# STM32WBA54 register map
File version: 1.0
CPU: CM33 r0p1, little endian, MPU, FPU, 4 interrupt priority bits
Registers are 32-bit, read-write, reset 0x0 unless marked. A register's access mark holds for its fields unless they carry their own. Offsets are from the block's base; [hi:lo] are bit positions.

## RCC (part 2 of 2) — Reset and clock control
Base 0x46020C00
Same registers: SEC_RCC 0x56020C00
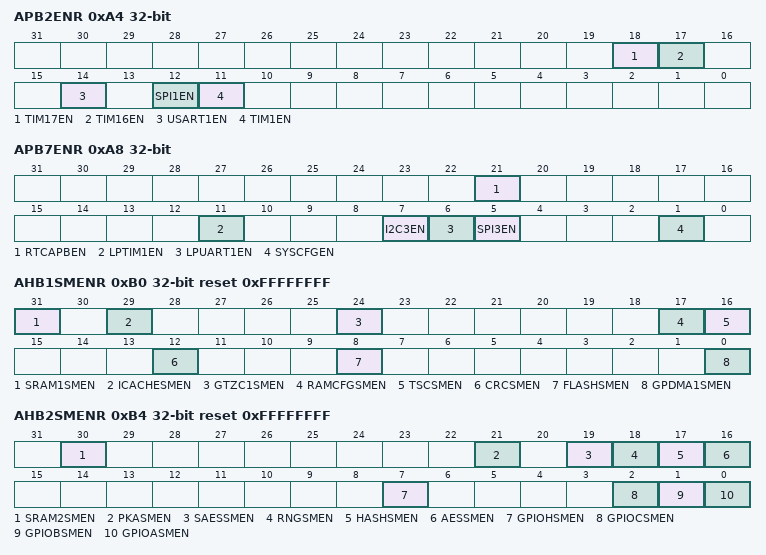
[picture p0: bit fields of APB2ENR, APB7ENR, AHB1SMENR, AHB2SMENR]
0xA4 APB2ENR — RCC APB2 peripheral clock enable register
  [18] TIM17EN — TIM17 bus and kernel clocks enable Set and cleared by software. Access can be secured by GTZC_TZSC TIM17SEC. When secure, a non-secure read/write access is RAZ/WI. It does not generate an illegal access interrupt. This bit can be protected against unprivileged access when secure with RCC SPRIV or when non-secure with RCC NSPRIV.
  [17] TIM16EN — TIM16 bus and kernel clocks enable Set and cleared by software. Access can be secured by GTZC_TZSC TIM16SEC. When secure, a non-secure read/write access is RAZ/WI. It does not generate an illegal access interrupt. This bit can be protected against unprivileged access when secure with RCC SPRIV or when non-secure with RCC NSPRIV.
  [14] USART1EN — USART1bus and kernel clocks enable Set and cleared by software. Access can be secured by GTZC_TZSC USART1SEC. When secure, a non-secure read/write access is RAZ/WI. It does not generate an illegal access interrupt. This bit can be protected against unprivileged access when secure with RCC SPRIV or when non-secure with RCC NSPRIV.
  [12] SPI1EN — SPI1 bus and kernel clocks enable Set and cleared by software. Access can be secured by GTZC_TZSC SPI1SEC. When secure, a non-secure read/write access is RAZ/WI. It does not generate an illegal access interrupt. This bit can be protected against unprivileged access when secure with RCC SPRIV or when non-secure with RCC NSPRIV.
  [11] TIM1EN — TIM1 bus and kernel clocks enable Set and cleared by software. Access can be secured by GTZC_TZSC TIM1SEC. When secure, a non-secure read/write access is RAZ/WI. It does not generate an illegal access interrupt. This bit can be protected against unprivileged access when secure with RCC SPRIV or when non-secure with RCC NSPRIV.
0xA8 APB7ENR — RCC APB7 peripheral clock enable register
  [21] RTCAPBEN — RTC and TAMP bus clock enable Set and cleared by software. Can only be accessed secure when one or more features in the RTC or TAMP is/are secure. When secure, a non-secure read/write access is RAZ/WI. It does not generate an illegal access interrupt. This bit can be protected against unprivileged access when secure with RCC SPRIV or when non-secure with RCC NSPRIV.
  [11] LPTIM1EN — LPTIM1 bus and kernel clocks enable Set and cleared by software. Access can be secured by GTZC_TZSC LPTIM1SEC. When secure, a non-secure read/write access is RAZ/WI. It does not generate an illegal access interrupt. This bit can be protected against unprivileged access when secure with RCC SPRIV or when non-secure with RCC NSPRIV.
  [7] I2C3EN — I2C3 bus and kernel clocks enable Set and cleared by software. Access can be secured by GTZC_TZSC I2C3SEC. When secure, a non-secure read/write access is RAZ/WI. It does not generate an illegal access interrupt. This bit can be protected against unprivileged access when secure with RCC SPRIV or when non-secure with RCC NSPRIV.
  [6] LPUART1EN — LPUART1 bus and kernel clocks enable Set and cleared by software. Access can be secured by GTZC_TZSC LPUART1SEC. When secure, a non-secure read/write access is RAZ/WI. It does not generate an illegal access interrupt. This bit can be protected against unprivileged access when secure with RCC SPRIV or when non-secure with RCC NSPRIV.
  [5] SPI3EN — SPI3 bus and kernel clocks enable Set and cleared by software. Access can be secured by GTZC_TZSC SPI3SEC. When secure, a non-secure read/write access is RAZ/WI. It does not generate an illegal access interrupt. This bit can be protected against unprivileged access when secure with RCC SPRIV or when non-secure with RCC NSPRIV.
  [1] SYSCFGEN — SYSCFG bus clock enable Set and cleared by software. Access can be secured by SYSCFG SYSCFGSEC. When secure, a non-secure read/write access is RAZ/WI. It does not generate an illegal access interrupt. This bit can be protected against unprivileged access when secure with RCC SPRIV or when non-secure with RCC NSPRIV.
0xB0 AHB1SMENR reset 0xFFFFFFFF — RCC AHB1 peripheral clocks enable in Sleep and Stop modes register
  [31] SRAM1SMEN — SRAM1 bus clock enable during Sleep and Stop modes Set and cleared by software. Access can be secured by GTZC_MPCBB1 SECx, INVSECSTATE. When secure, a non-secure read/write access is RAZ/WI. It does not generate an illegal access interrupt. This bit can be protected against unprivileged access when secure with RCC SPRIV or when non-secure with RCC NSPRIV.
  [29] ICACHESMEN — ICACHE bus clock enable during Sleep and Stop modes Set and cleared by software. Access can be secured by GTZC_TZSC ICACHE_REGSEC. When secure, a non-secure read/write access is RAZ/WI. It does not generate an illegal access interrupt. This bit can be protected against unprivileged access when secure with RCC SPRIV or when non-secure with RCC NSPRIV..
  [24] GTZC1SMEN — GTZC1 bus clock enable during Sleep and Stop modes Set and cleared by software. Can only be accessed secure when one device is secure (TZEN = 1). When secure, a non-secure read/write access is RAZ/WI. It does not generate an illegal access interrupt. This bit can be protected against unprivileged access when secure with RCC SPRIV or when non-secure with RCC NSPRIV.
  [17] RAMCFGSMEN — RAMCFG bus clock enable during Sleep and Stop modes Set and cleared by software. Access can be secured by GTZC_TZSC RAMCFGSEC. When secure, a non-secure read/write access is RAZ/WI. It does not generate an illegal access interrupt. This bit can be protected against unprivileged access when secure with RCC SPRIV or when non-secure with RCC NSPRIV.
  [16] TSCSMEN — TSC bus clock enable during Sleep and Stop modes Set and cleared by software. Access can be secured by GTZC_TZSC TSCSEC. When secure, a non-secure read/write access is RAZ/WI. It does not generate an illegal access interrupt. This bit can be protected against unprivileged access when secure with RCC SPRIV or when non-secure with RCC NSPRIV..
  [12] CRCSMEN — CRC bus clock enable during Sleep and Stop modes Set and cleared by software. Access can be secured by GTZC_TZSC CRCSEC. When secure, a non-secure read/write access is RAZ/WI. It does not generate an illegal access interrupt. This bit can be protected against unprivileged access when secure with RCC SPRIV or when non-secure with RCC NSPRIV.
  [8] FLASHSMEN — FLASH bus clock enable during Sleep and Stop modes Set and cleared by software. Can only be accessed secured when the Flash security state is secure. When secure, a non-secure read/write access is RAZ/WI. It does not generate an illegal access interrupt. This bit can be protected against unprivileged access when secure with RCC SPRIV or when non-secure with RCC NSPRIV.
  [0] GPDMA1SMEN — GPDMA1 bus clock enable during Sleep and Stop modes Set and cleared by software. Access can be secured by GPDMA1 SECx. When secure, a non-secure read/write access is RAZ/WI. It does not generate an illegal access interrupt. This bit can be protected against unprivileged access when secure with RCC SPRIV or when non-secure with RCC NSPRIV. Note: This bit must be set to allow the peripheral to wake up from Stop modes.
0xB4 AHB2SMENR reset 0xFFFFFFFF — RCC AHB2 peripheral clocks enable in Sleep and Stop modes register
  [30] SRAM2SMEN — SRAM2 bus clock enable during Sleep and Stop modes Set and cleared by software. Access can be secured by GTZC_MPCBB2 SECx, INVSECSTATE. When secure, a non-secure read/write access is RAZ/WI. It does not generate an illegal access interrupt. This bit can be protected against unprivileged access when secure with RCC SPRIV or when non-secure with RCC NSPRIV.
  [21] PKASMEN — PKA bus clock enable during Sleep and Stop modes Set and cleared by software. Access can be secured by GTZC_TZSC PKASEC. When secure, a non-secure read/write access is RAZ/WI. It does not generate an illegal access interrupt. This bit can be protected against unprivileged access when secure with RCC SPRIV or when non-secure with RCC NSPRIV.
  [19] SAESSMEN — SAES accelerator bus clock enable during Sleep and Stop modes Set and cleared by software. Access can be secured by GTZC_TZSC SAESSEC. When secure, a non-secure read/write access is RAZ/WI. It does not generate an illegal access interrupt. This bit can be protected against unprivileged access when secure with RCC SPRIV or when non-secure with RCC NSPRIV.
  [18] RNGSMEN — Random number generator (RNG) bus and kernel clocks enable during Sleep and Stop modes Set and cleared by software. Access can be secured by GTZC_TZSC RNGSEC. When secure, a non-secure read/write access is RAZ/WI. It does not generate an illegal access interrupt. This bit can be protected against unprivileged access when secure with RCC SPRIV or when non-secure with RCC NSPRIV.
  [17] HASHSMEN — HASH bus clock enable during Sleep and Stop modes Set and cleared by software. Access can be secured by GTZC_TZSC HASHSEC. When secure, a non-secure read/write access is RAZ/WI. It does not generate an illegal access interrupt. This bit can be protected against unprivileged access when secure with RCC SPRIV or when non-secure with RCC NSPRIV.
  [16] AESSMEN — AES bus clock enable during Sleep and Stop modes Set and cleared by software. Access can be secured by GTZC_TZSC AESSEC. When secure, a non-secure read/write access is RAZ/WI. It does not generate an illegal access interrupt. This bit can be protected against unprivileged access when secure with RCC SPRIV or when non-secure with RCC NSPRIV.
  [7] GPIOHSMEN — IO port H bus clock enable during Sleep and Stop modes Set and cleared by software. Access can be secured by GPIOH SECx. When secure, a non-secure read/write access is RAZ/WI. It does not generate an illegal access interrupt. This bit can be protected against unprivileged access when secure with RCC SPRIV or when non-secure with RCC NSPRIV.
  [2] GPIOCSMEN — IO port C bus clock enable during Sleep and Stop modes Set and cleared by software. Access can be secured by GPIOC SECx. When secure, a non-secure read/write access is RAZ/WI. It does not generate an illegal access interrupt. This bit can be protected against unprivileged access when secure with RCC SPRIV or when non-secure with RCC NSPRIV.
  [1] GPIOBSMEN — IO port B bus clock enable during Sleep and Stop modes Set and cleared by software. Access can be secured by GPIOB SECx. When secure, a non-secure read/write access is RAZ/WI. It does not generate an illegal access interrupt. This bit can be protected against unprivileged access when secure with RCC SPRIV or when non-secure with RCC NSPRIV.
  [0] GPIOASMEN — IO port A bus clock enable during Sleep and Stop modes Set and cleared by software. Access can be secured by GPIOA SECx. When secure, a non-secure read/write access is RAZ/WI. It does not generate an illegal access interrupt. This bit can be protected against unprivileged access when secure with RCC SPRIV or when non-secure with RCC NSPRIV.
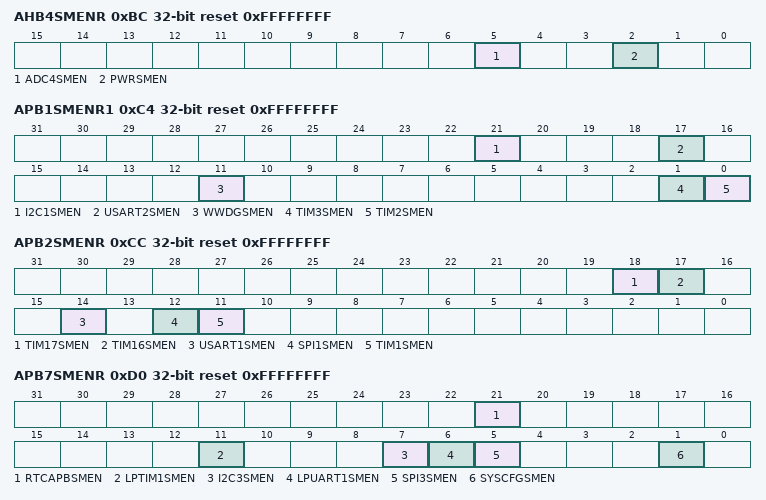
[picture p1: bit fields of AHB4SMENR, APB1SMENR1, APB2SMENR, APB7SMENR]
0xBC AHB4SMENR reset 0xFFFFFFFF — RCC AHB4 peripheral clocks enable in Sleep and Stop modes register
  [5] ADC4SMEN — ADC4 bus and kernel clocks enable during Sleep and Stop modes Set and cleared by software. Access can be secured by GTZC_TZSC ADC4SEC. When secure, a non-secure read/write access is RAZ/WI. It does not generate an illegal access interrupt. This bit can be protected against unprivileged access when secure with RCC SPRIV or when non-secure with RCC NSPRIV. Note: This bit must be set to allow the peripheral to wake up from Stop modes.
  [2] PWRSMEN — PWR bus clock enable during Sleep and Stop modes Set and cleared by software. Can only be accessed secure when one or more features in the PWR is/are secure. When secure, a non-secure read/write access is RAZ/WI. It does not generate an illegal access interrupt. This bit can be protected against unprivileged access when secure with RCC SPRIV or when non-secure with RCC NSPRIV.
0xC0 AHB5SMENR reset 0xFFFFFFFF — RCC AHB5 peripheral clocks enable in Sleep and Stop modes register
  [0] RADIOSMEN — 2.4 GHz RADIO bus clock enable during Sleep and Stop modes when the 2.4 GHz RADIO is active. Set and cleared by software. Access can be secured by GTZC_TZSC RADIOSEC. When secure, a non-secure read/write access is RAZ/WI. It does not generate an illegal access interrupt. This bit can be protected against unprivileged access when secure with RCC SPRIV or when non-secure with RCC NSPRIV.
0xC4 APB1SMENR1 reset 0xFFFFFFFF — RCC APB1 peripheral clocks enable in Sleep and Stop modes register 1
  [21] I2C1SMEN — I2C1 bus and kernel clocks enable during Sleep and Stop modes Set and cleared by software. Access can be secured by GTZC_TZSC I2C1SEC. When secure, a non-secure read/write access is RAZ/WI. It does not generate an illegal access interrupt. This bit can be protected against unprivileged access when secure with RCC SPRIV or when non-secure with RCC NSPRIV. Note: This bit must be set to allow the peripheral to wake up from Stop modes.
  [17] USART2SMEN — USART2 bus and kernel clocks enable during Sleep and Stop modes Set and cleared by software. Access can be secured by GTZC_TZSC USART2SEC. When secure, a non-secure read/write access is RAZ/WI. It does not generate an illegal access interrupt. This bit can be protected against unprivileged access when secure with RCC SPRIV or when non-secure with RCC NSPRIV. Note: This bit must be set to allow the peripheral to wake up from Stop modes.
  [11] WWDGSMEN — Window watchdog bus clock enable during Sleep and Stop modes Set and cleared by software. This bit is forced to 1 by hardware when the hardware WWDG option is activated. Access can be secured by GTZC_TZSC WWDGSEC. When secure, a non-secure read/write access is RAZ/WI. It does not generate an illegal access interrupt. This bit can be protected against unprivileged access when secure with RCC SPRIV or when non-secure with RCC NSPRIV.
  [1] TIM3SMEN — TIM3 bus and kernel clocks enable during Sleep and Stop modes Set and cleared by software. Access can be secured by GTZC_TZSC TIM3SEC. When secure, a non-secure read/write access is RAZ/WI. It does not generate an illegal access interrupt. This bit can be protected against unprivileged access when secure with RCC SPRIV or when non-secure with RCC NSPRIV.
  [0] TIM2SMEN — TIM2 bus and kernel clocks enable during Sleep and Stop modes Set and cleared by software. Access can be secured by GTZC_TZSC TIM2SEC. When secure, a non-secure read/write access is RAZ/WI. It does not generate an illegal access interrupt. This bit can be protected against unprivileged access when secure with RCC SPRIV or when non-secure with RCC NSPRIV.
0xC8 APB1SMENR2 reset 0xFFFFFFFF — RCC APB1 peripheral clocks enable in Sleep and Stop modes register 2
  [5] LPTIM2SMEN — LPTIM2 bus and kernel clocks enable during Sleep and Stop modes Set and cleared by software. Access can be secured by GTZC_TZSC LPTIM2SEC. When secure, a non-secure read/write access is RAZ/WI. It does not generate an illegal access interrupt. This bit can be protected against unprivileged access when secure with RCC SPRIV or when non-secure with RCC NSPRIV. Note: This bit must be set to allow the peripheral to wake up from Stop modes.
0xCC APB2SMENR reset 0xFFFFFFFF — RCC APB2 peripheral clocks enable in Sleep and Stop modes register
  [18] TIM17SMEN — TIM17 bus and kernel clocks enable during Sleep and Stop modes Set and cleared by software. Access can be secured by GTZC_TZSC TIM17SEC. When secure, a non-secure read/write access is RAZ/WI. It does not generate an illegal access interrupt. This bit can be protected against unprivileged access when secure with RCC SPRIV or when non-secure with RCC NSPRIV.
  [17] TIM16SMEN — TIM16 bus and kernel clocks enable during Sleep and Stop modes Set and cleared by software. Access can be secured by GTZC_TZSC TIM16SEC. When secure, a non-secure read/write access is RAZ/WI. It does not generate an illegal access interrupt. This bit can be protected against unprivileged access when secure with RCC SPRIV or when non-secure with RCC NSPRIV.
  [14] USART1SMEN — USART1 bus and kernel clocks enable during Sleep and Stop modes Set and cleared by software. Access can be secured by GTZC_TZSC USART1SEC. When secure, a non-secure read/write access is RAZ/WI. It does not generate an illegal access interrupt. This bit can be protected against unprivileged access when secure with RCC SPRIV or when non-secure with RCC NSPRIV. Note: This bit must be set to allow the peripheral to wake up from Stop modes.
  [12] SPI1SMEN — SPI1 bus and kernel clocks enable during Sleep and Stop modes Set and cleared by software. Access can be secured by GTZC_TZSC SPI1SEC. When secure, a non-secure read/write access is RAZ/WI. It does not generate an illegal access interrupt. This bit can be protected against unprivileged access when secure with RCC SPRIV or when non-secure with RCC NSPRIV. Note: This bit must be set to allow the peripheral to wake up from Stop modes.
  [11] TIM1SMEN — TIM1 bus and kernel clocks enable during Sleep and Stop modes Set and cleared by software. Access can be secured by GTZC_TZSC TIM1SEC. When secure, a non-secure read/write access is RAZ/WI. It does not generate an illegal access interrupt. This bit can be protected against unprivileged access when secure with RCC SPRIV or when non-secure with RCC NSPRIV.
0xD0 APB7SMENR reset 0xFFFFFFFF — RCC APB7 peripheral clock enable in Sleep and Stop modes register
  [21] RTCAPBSMEN — RTC and TAMP APB clock enable during Sleep and Stop modes Set and cleared by software. Can only be accessed secure when one or more features in the RTC or TAMP is/are secure. When secure, a non-secure read/write access is RAZ/WI. It does not generate an illegal access interrupt. This bit can be protected against unprivileged access when secure with RCC SPRIV or when non-secure with RCC NSPRIV. Note: This bit must be set to allow the peripheral to wake up from Stop modes.
  [11] LPTIM1SMEN — LPTIM1 bus and kernel clocks enable during Sleep and Stop modes Set and cleared by software. Access can be secured by GTZC_TZSC LPTIM1SEC. When secure, a non-secure read/write access is RAZ/WI. It does not generate an illegal access interrupt. This bit can be protected against unprivileged access when secure with RCC SPRIV or when non-secure with RCC NSPRIV. Note: This bit must be set to allow the peripheral to wake up from Stop modes.
  [7] I2C3SMEN — I2C3 bus and kernel clocks enable during Sleep and Stop modes Set and cleared by software. Access can be secured by GTZC_TZSC I2C3SEC. When secure, a non-secure read/write access is RAZ/WI. It does not generate an illegal access interrupt. This bit can be protected against unprivileged access when secure with RCC SPRIV or when non-secure with RCC NSPRIV. Note: This bit must be set to allow the peripheral to wake up from Stop modes.
  [6] LPUART1SMEN — LPUART1 bus and kernel clocks enable during Sleep and Stop modes Set and cleared by software. Access can be secured by GTZC_TZSC LPUART1SEC. When secure, a non-secure read/write access is RAZ/WI. It does not generate an illegal access interrupt. This bit can be protected against unprivileged access when secure with RCC SPRIV or when non-secure with RCC NSPRIV. Note: This bit must be set to allow the peripheral to wake up from Stop modes.
  [5] SPI3SMEN — SPI3 bus and kernel clocks enable during Sleep and Stop modes Set and cleared by software. Access can be secured by GTZC_TZSC SPI3SEC. When secure, a non-secure read/write access is RAZ/WI. It does not generate an illegal access interrupt. This bit can be protected against unprivileged access when secure with RCC SPRIV or when non-secure with RCC NSPRIV. Note: This bit must be set to allow the peripheral to wake up from Stop modes.
  [1] SYSCFGSMEN — SYSCFG bus clock enable during Sleep and Stop modes Set and cleared by software. Access can be secured by SYSCFG SYSCFGSEC. When secure, a non-secure read/write access is RAZ/WI. It does not generate an illegal access interrupt. This bit can be protected against unprivileged access when secure with RCC SPRIV or when non-secure with RCC NSPRIV.
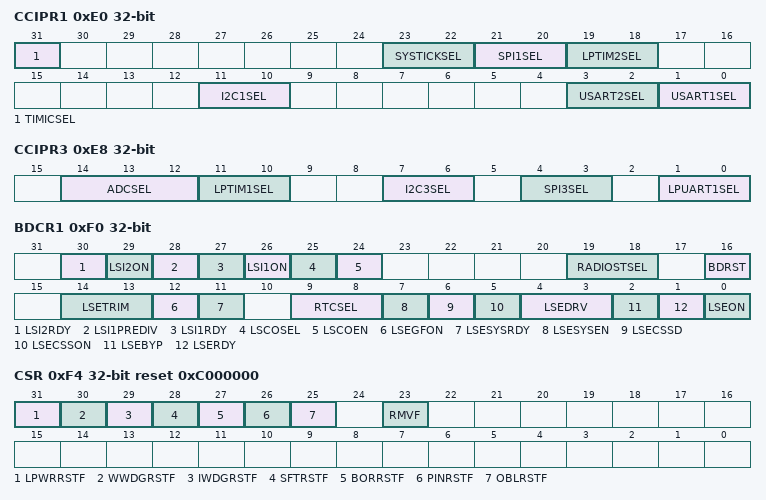
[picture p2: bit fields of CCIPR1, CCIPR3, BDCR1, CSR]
0xE0 CCIPR1 — RCC peripherals independent clock configuration register 1
  [31] TIMICSEL — Clocks sources for TIM16,TIM17 and LPTIM2 internal input capture When the TIMICSEL bit is set, the TIM16, TIM17 and LPTIM2 internal input capture can be connected to HSI16/256. When TIMICSEL is cleared, the HSI16, clock sources cannot be selected as TIM16, TIM17 or LPTIM2 internal input capture. Access can be secured by GTZC_TZSC TIM16SEC, TIM17SEC, or LPTIM2SEC. When secure, a non-secure read/write access is RAZ/WI. It does not generate an illegal access interrupt. This bit can be protected against unprivileged access when secure with RCC SPRIV or when non-secure with RCC NSPRIV. Note: The clock division must be disabled (TIMICSEL configured to 0) before selecting or changing a clock sources division.
  [23:22] SYSTICKSEL — SysTick clock source selection These bits are used to select the SysTick clock source. Access can be secured by RCC SYSCLKSEC. When secure, a non-secure read/write access is RAZ/WI. It does not generate an illegal access interrupt. This bit can be protected against unprivileged access when secure with RCC SPRIV or when non-secure with RCC NSPRIV. Note: When LSE or LSI is selected, the AHB frequency must be at least four times higher than the LSI or LSE frequency. In addition, a jitter up to one hclk1 cycle is introduced, due to the LSE or LSI sampling with hclk1 in the SysTick circuitry.
  [21:20] SPI1SEL — SPI1 kernel clock source selection These bits are used to select the SPI1 kernel clock source. Access can be secured by GTZC_TZSC SPI1SEC. When secure, a non-secure read/write access is RAZ/WI. It does not generate an illegal access interrupt. This bit can be protected against unprivileged access when secure with RCC SPRIV or when non-secure with RCC NSPRIV. Note: The SPI1 is functional in Stop 0 and Stop 1 mode only when the kernel clock is HSI16.
  [19:18] LPTIM2SEL — Low-power timer 2 kernel clock source selection These bits are used to select the LPTIM2 kernel clock source. Access can be secured by GTZC_TZSC LPTIM2SEC. When secure, a non-secure read/write access is RAZ/WI. It does not generate an illegal access interrupt. This bit can be protected against unprivileged access when secure with RCC SPRIV or when non-secure with RCC NSPRIV. Note: The LPTIM2 is functional in Stop 0 and Stop 1 mode only when the kernel clock is LSI, LSE or HSI16 if HSIKERON = 1.
  [11:10] I2C1SEL — I2C1 kernel clock source selection These bits are used to select the I2C1 kernel clock source. Access can be secured by GTZC_TZSC I2C1SEC. When secure, a non-secure read/write access is RAZ/WI. It does not generate an illegal access interrupt. This bit can be protected against unprivileged access when secure with RCC SPRIV or when non-secure with RCC NSPRIV. Note: The I2C1 is functional in Stop 0 and Stop 1 mode only when the kernel clock is HSI16.
  [3:2] USART2SEL — USART2 kernel clock source selection This bits are used to select the USART2 kernel clock source. Access can be secured by GTZC_TZSC USART2SEC. When secure, a non-secure read/write access is RAZ/WI. It does not generate an illegal access interrupt. This bit can be protected against unprivileged access when secure with RCC SPRIV or when non-secure with RCC NSPRIV. Note: The USART2 is functional in Stop 0 and Stop 1 mode only when the kernel clock is HSI16 or LSE.
  [1:0] USART1SEL — USART1 kernel clock source selection This bits are used to select the USART1 kernel clock source. Access can be secured by GTZC_TZSC USART1SEC. When secure, a non-secure read/write access is RAZ/WI. It does not generate an illegal access interrupt. This bit can be protected against unprivileged access when secure with RCC SPRIV or when non-secure with RCC NSPRIV. Note: The USART1 is functional in Stop 0 and Stop 1 mode only when the kernel clock is HSI16 or LSE.
0xE4 CCIPR2 — RCC peripherals independent clock configuration register 2
  [13:12] RNGSEL — RNGSEL kernel clock source selection These bits allow to select the RNG kernel clock source. Access can be secured by GTZC_TZSC RNGSEC. When secure, a non-secure read/write access is RAZ/WI. It does not generate an illegal access interrupt. This bit can be protected against unprivileged access when secure with RCC SPRIV or when non-secure with RCC NSPRIV.
0xE8 CCIPR3 — RCC peripherals independent clock configuration register 3
  [14:12] ADCSEL — ADC4 kernel clock source selection These bits are used to select the ADC4 kernel clock source. Access can be secured by GTZC_TZSC ADC4SEC. When secure, a non-secure read/write access is RAZ/WI. It does not generate an illegal access interrupt. This bit can be protected against unprivileged access when secure with RCC SPRIV or when non-secure with RCC NSPRIV. others: reserved Note: The ADC4 is functional in Stop modes only when the kernel clock is HSI16.
  [11:10] LPTIM1SEL — LPTIM1 kernel clock source selection These bits are used to select the LPTIM1 kernel clock source. Access can be secured by GTZC_TZSC LPTIM1SEC. When secure, a non-secure read/write access is RAZ/WI. It does not generate an illegal access interrupt. This bit can be protected against unprivileged access when secure with RCC SPRIV or when non-secure with RCC NSPRIV. Note: The LPTIM1 is functional in Stop modes only when the kernel clock is LSI, LSE, HSI16 with HSIKERON = 1.
  [7:6] I2C3SEL — I2C3 kernel clock source selection These bits are used to select the I2C3 kernel clock source. Access can be secured by GTZC_TZSC I2C3SEC. When secure, a non-secure read/write access is RAZ/WI. It does not generate an illegal access interrupt. This bit can be protected against unprivileged access when secure with RCC SPRIV or when non-secure with RCC NSPRIV. Note: The I2C3 is functional in Stop modes only when the kernel clock is HSI16
  [4:3] SPI3SEL — SPI3 kernel clock source selection These bits are used to select the SPI3 kernel clock source. Access can be secured by GTZC_TZSC SPI3SEC. When secure, a non-secure read/write access is RAZ/WI. It does not generate an illegal access interrupt. This bit can be protected against unprivileged access when secure with RCC SPRIV or when non-secure with RCC NSPRIV. Note: The SPI3 is functional in Stop modes only when the kernel clock is HSI16.
  [1:0] LPUART1SEL — LPUART1 kernel clock source selection These bits are used to select the LPUART1 kernel clock source. Access can be secured by GTZC_TZSC LPUART1SEC. When secure, a non-secure read/write access is RAZ/WI. It does not generate an illegal access interrupt. This bit can be protected against unprivileged access when secure with RCC SPRIV or when non-secure with RCC NSPRIV. Note: The LPUART1 is functional in Stop modes only when the kernel clock is HSI16 or LSE.
0xF0 BDCR1 access per field reset not defined — RCC backup domain control register
  [30] LSI2RDY ro — LSI2 oscillator ready
  [29] LSI2ON rw — LSI2 oscillator enable
  [28] LSI1PREDIV rw — LSI1 Low-speed clock divider configuration Set and cleared by software to enable the LSI1 division. This bit can be written only when the LSI1 is disabled (LSI1ON = 0 and LSI1RDY = 0). The LSI1PREDIV cannot be changed if the LSI1 is used by the IWDG or by the RTC. Access can be secured by RCC LSISEC. When secure, a non-secure read/write access is RAZ/WI. It does not generate an illegal access interrupt. This bit can be protected against unprivileged access when secure with RCC SPRIV or when non-secure with RCC NSPRIV.
  [27] LSI1RDY ro — LSI1 oscillator ready Set and cleared by hardware to indicate when the LSI1 oscillator is stable. After the LSI1ON bit is cleared, LSI1RDY goes low after three internal low-speed oscillator clock cycles. This bit is set when the LSI1 is used by IWDG or RTC, even if LSI1ON = 0. Access can be secured by RCC LSISEC. When secure, a non-secure read/write access is RAZ/WI. It does not generate an illegal access interrupt. This bit can be protected against unprivileged access when secure with RCC SPRIV or when non-secure with RCC NSPRIV.
  [26] LSI1ON rw — LSI1 oscillator enable Set and cleared by software. Access can be secured by RCC LSISEC. When secure, a non-secure read/write access is RAZ/WI. It does not generate an illegal access interrupt. This bit can be protected against unprivileged access when secure with RCC SPRIV or when non-secure with RCC NSPRIV.
  [25] LSCOSEL rw — Low-speed clock output selection Set and cleared by software. Access can be secured by RCC LSISEC and/or RCC LSESEC. When secure, a non-secure read/write access is RAZ/WI. It does not generate an illegal access interrupt. This bit can be protected against unprivileged access when secure with RCC SPRIV or when non-secure with RCC NSPRIV.
  [24] LSCOEN rw — Low-speed clock output (LSCO) enable Set and cleared by software. Access can be secured by RCC LSISEC and/or RCC LSESEC. When secure, a non-secure read/write access is RAZ/WI. It does not generate an illegal access interrupt. This bit can be protected against unprivileged access when secure with RCC SPRIV or when non-secure with RCC NSPRIV.
  [19:18] RADIOSTSEL rw — 2.4 GHz RADIO sleep timer kernel clock enable and selection Set and cleared by software. Access can be secured by GTZC_TZSC RADIOSEC. When secure, a non-secure read/write access is RAZ/WI. It does not generate an illegal access interrupt. This bit can be protected against unprivileged access when secure with RCC SPRIV or when non-secure with RCC NSPRIV.
  [16] BDRST rw — Backup domain software reset Set and cleared by software. Can only be accessed secure when one or more features in the RTC or TAMP is secure. When secure, a non-secure read/write access is RAZ/WI. It does not generate an illegal access interrupt. This bit can be protected against unprivileged access when secure with RCC SPRIV or when non-secure with RCC NSPRIV.
  [14:13] LSETRIM rw — LSE trimming These bits are initialized at startup and after OBL_LAUNCH with SBF cleared with the factory-programmed LSE calibration value. Set and cleared by software. These bits must be modified only once after a BOR reset or an OBL_LAUNCH and before enabling LSE with LSEON (when both LSEON = 0 and LSERDY= 0). Access can be secured by RCC LSESEC. When secure, a non-secure read/write access is RAZ/WI. It does not generate an illegal access interrupt. This bit can be protected against unprivileged access when secure with RCC SPRIV or when non-secure with RCC NSPRIV. Note: OBL_LAUNCH of this field occurs only when SBF is cleared and must then only be started by software when LSE oscillator is disabled, LSEON = 0 and LSERDY = 0.
  [12] LSEGFON rw — LSE clock glitch filter enable Set and cleared by hardware to enable the LSE glitch filter. This bit can be written only when the LSE is disabled (LSEON = 0 and LSERDY = 0). Access can be secured by RCC LSESEC. When secure, a non-secure read/write access is RAZ/WI. It does not generate an illegal access interrupt. This bit can be protected against unprivileged access when secure with RCC SPRIV or when non-secure with RCC NSPRIV.
  [11] LSESYSRDY ro — LSE system clock (LSESYS) ready Set and cleared by hardware to indicate when the LSE system clock is stable.When the LSESYSEN bit is set, the LSESYSRDY flag is set after two LSE clock cycles. The LSE clock must be already enabled and stable (LSEON and LSERDY are set). When the LSEON bit is cleared, LSERDY goes low after six external low-speed oscillator clock cycles. Access can be secured by RCC LSESEC. When secure, a non-secure read/write access is RAZ/WI. It does not generate an illegal access interrupt. This bit can be protected against unprivileged access when secure with RCC SPRIV or when non-secure with RCC NSPRIV.
  [9:8] RTCSEL rw — RTC and TAMP kernel clock source enable and selection Set by software to enable and select the clock source for the RTC. Can only be accessed secure when one or more features in the RTC or TAMP is/are secure. When secure, a non-secure read/write access is RAZ/WI. It does not generate an illegal access interrupt. This bit can be protected against unprivileged access when secure with RCC SPRIV or when non-secure with RCC NSPRIV.
  [7] LSESYSEN rw — LSE system clock (LSESYS) enable Set by software to enable the LSE system clock generated by RCC. The lsesys clock is used for peripherals (USART, LPUART, LPTIM, RNG, 2.4 GHz RADIO) and functions (LSCO, MCO, TIM triggers, LPTIM trigger) excluding the RTC, TAMP and LSECSS. Access can be secured by RCC LSESEC. When secure, a non-secure read/write access is RAZ/WI. It does not generate an illegal access interrupt. This bit can be protected against unprivileged access when secure with RCC SPRIV or when non-secure with RCC NSPRIV.
  [6] LSECSSD ro — Low speed external clock security, LSE failure Detection Set by hardware to indicate when a failure is detected by the LSECCS on the external 32kHz oscillator. Reset when LSCSSON bit is cleared. Access can be secured by RCC LSESEC. When secure, a non-secure read/write access is RAZ/WI. It does not generate an illegal access interrupt. This bit can be protected against unprivileged access when secure with RCC SPRIV or when non-secure with RCC NSPRIV.
  [5] LSECSSON rw — Low speed external clock security enable Set by software to enable the LSECSS. LSECSSON must be enabled after the LSE oscillator is enabled (LSEON bit enabled) and ready (LSERDY flag set by hardware) and after the RTCSEL bit is selected. Once enabled, this bit cannot be disabled, except after a LSE failure detection (LSECSSD=1). In that case, the software must disable the LSECSSON bit. Access can be secured by RCC LSESEC. When secure, a non-secure read/write access is RAZ/WI. It does not generate an illegal access interrupt. This bit can be protected against unprivileged access when secure with RCC SPRIV or when non-secure with RCC NSPRIV.
  [4:3] LSEDRV rw — LSE oscillator drive capability Set by software to modulate the drive capability of the LSE oscillator. LSEDRV must be programmed to a different value than 0 before enabling the LSE oscillator in 'Xtal' mode. Access can be secured by RCC LSESEC. When secure, a non-secure read/write access is RAZ/WI. It does not generate an illegal access interrupt. This bit can be protected against unprivileged access when secure with RCC SPRIV or when non-secure with RCC NSPRIV. Note: The oscillator is in 'Xtal mode' when it is not in bypass mode.
  [2] LSEBYP rw — LSE oscillator bypass Set and cleared by software to bypass oscillator in debug mode. This bit can be written only when the external 32kHz oscillator is disabled (LSEON = 0 and LSERDY = 0). Access can be secured by RCC LSESEC. When secure, a non-secure read/write access is RAZ/WI. It does not generate an illegal access interrupt. This bit can be protected against unprivileged access when secure with RCC SPRIV or when non-secure with RCC NSPRIV.
  [1] LSERDY ro — LSE oscillator ready Set and cleared by hardware to indicate when the external 32kHz oscillator is stable. After the LSEON bit is cleared, LSERDY goes low after six external low-speed oscillator clock cycles. Access can be secured by RCC LSESEC. When secure, a non-secure read/write access is RAZ/WI. It does not generate an illegal access interrupt. This bit can be protected against unprivileged access when secure with RCC SPRIV or when non-secure with RCC NSPRIV.
  [0] LSEON rw — LSE oscillator enable Set and cleared by software. Access can be secured by RCC LSESEC. When secure, a non-secure read/write access is RAZ/WI. It does not generate an illegal access interrupt. This bit can be protected against unprivileged access when secure with RCC SPRIV or when non-secure with RCC NSPRIV.
0xF4 CSR access per field reset 0xC000000 — RCC control/status register
  [31] LPWRRSTF ro — Low-power reset flag Set by hardware when a reset occurs due to illegal Stop and Standby modes entry. Cleared by writing to the RMVF bit.
  [30] WWDGRSTF ro — Window watchdog reset flag Set by hardware when a window watchdog reset occurs. Cleared by writing to the RMVF bit.
  [29] IWDGRSTF ro — Independent watchdog reset flag Set by hardware when an independent watchdog reset domain occurs. Cleared by writing to the RMVF bit.
  [28] SFTRSTF ro — Software reset flag Set by hardware when a software reset occurs. Cleared by writing to the RMVF bit.
  [27] BORRSTF ro — BOR flag Set by hardware when a BOR occurs. Cleared by writing to the RMVF bit.
  [26] PINRSTF ro — NRST pin reset flag Set by hardware when a reset from the NRST pin occurs. Cleared by writing to the RMVF bit.
  [25] OBLRSTF ro — Option byte loader reset flag Set by hardware when a reset from the option byte loading occurs. Cleared by writing to the RMVF bit.
  [23] RMVF rw — Remove reset flag Set by software to clear the reset flags. Access can be secured by RCC RMVFSEC. When secure, a non-secure read/write access is RAZ/WI. It does not generate an illegal access interrupt. This bit can be protected against unprivileged access when secure with RCC SPRIV or when non-secure with RCC NSPRIV.
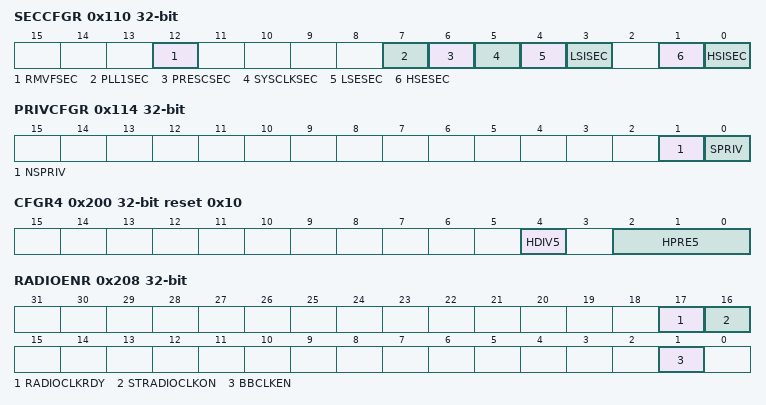
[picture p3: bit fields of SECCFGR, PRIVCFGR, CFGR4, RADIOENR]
0x110 SECCFGR — RCC secure configuration register
  [12] RMVFSEC — Remove reset flag security Set and reset by software.
  [7] PLL1SEC — PLL1 clock configuration and status bits security Set and reset by software.
  [6] PRESCSEC — AHBx/APBx prescaler configuration bits security Set and reset by software.
  [5] SYSCLKSEC — SYSCLK selection, clock output on MCO configuration security Set and reset by software.
  [4] LSESEC — LSE clock configuration and status bits security Set and reset by software.
  [3] LSISEC — LSI clock configuration and status bits security Set and reset by software.
  [1] HSESEC — HSE32 clock configuration bits, status bits and HSECSS security Set and reset by software.
  [0] HSISEC — HSI16 clock configuration and status bits security Set and reset by software.
0x114 PRIVCFGR — RCC privilege configuration register
  [1] NSPRIV — RCC non-secure functions privilege configuration Set and reset by software. This bit can be written only by privileged access, secure or non-secure.
  [0] SPRIV — RCC secure functions privilege configuration Set and reset by software. This bit can be written only by a secure privileged access.
0x200 CFGR4 reset 0x10 — RCC clock configuration register 2
  [4] HDIV5 — AHB5 divider when SWS select HSI16 or HSE32 Set and reset by software. Set to 1 by hardware when entering Stop 1 mode. When SYSCLK source indicated by SWS is HSI16 or HSE32: HDIV5 is taken into account When SYSCLK source indicated by SWS is PLL1: HDIV5 is taken not taken into account Depending on the device voltage range, the software must set this bit correctly to ensure that the AHB5 frequency does not exceed the maximum allowed frequency (for more details, refer to Table99). After a write operation to this bit and before decreasing the voltage range, this register must be read to be sure that the new value is taken into account.
  [2:0] HPRE5 — AHB5 prescaler when SWS select PLL1 Set and cleared by software to control the division factor of the AHB5 clock (hclk5). Must not be changed when SYSCLK source indicated by SWS is PLL1. When SYSCLK source indicated by SWS is not PLL1: HPRE5 is not taken into account. When SYSCLK source indicated by SWS is PLL1: HPRE5 is taken into account, from the moment the system clock switch occurs Depending on the device voltage range, the software must set these bits correctly to ensure that the AHB5 frequency does not exceed the maximum allowed frequency (for more details, refer to Table99: SYSCLK and bus maximum frequency). After a write operation to these bits and before decreasing the voltage range, this register must be read to be sure that the new value is taken into account. 0xx: hclk5 = SYSCLK not divided
0x208 RADIOENR access per field — RCC RADIO peripheral clock enable register
  [17] RADIOCLKRDY ro — 2.4 GHz RADIO bus clock ready. Set and cleared by hardware to indicate that the 2.4 GHz RADIO bus clock is ready and the 2.4 GHz RADIO registers can be accessed. Note: Once both RADIOEN and STRADIOCLKON are cleared, RADIOCLKRDY goes low after three hclk5 clock cycles.
  [16] STRADIOCLKON rw — 2.4 GHz RADIO bus clock enable and HSE32 oscillator enable by 2.4 GHz RADIO sleep timer wakeup event Set by hardware on a 2.4 GHz RADIO sleep timer wakeup event. Cleared by software writing zero to this bit. Note: Before accessing the 2.4 GHz RADIO registers the RADIOCLKRDY bit must be checked.
  [1] BBCLKEN rw — 2.4 GHz RADIO baseband kernel clock (aclk) enable Set and cleared by software. Note: The HSE32 oscillator needs to be enabled by either HSEON or STRADIOCLKON.
0x210 ECSCR1 reset 0x200000 — RCC external clock sources calibration register 1
  [21:16] HSETRIM — HSE32 clock trimming These bits provide user-programmable capacitor trimming value. It can be programmed to adjust the HSE32 oscillator frequency.
